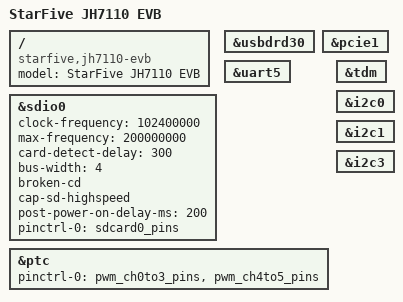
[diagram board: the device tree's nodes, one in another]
// SPDX-License-Identifier: GPL-2.0 OR MIT
/*
 * Copyright (C) 2022 StarFive Technology Co., Ltd.
 * Copyright (C) 2022 Hal Feng <hal.feng@starfivetech.com>
 */

/dts-v1/;
#include "jh7110-evb.dtsi"
#include "codecs/sf_tdm.dtsi"

/ {
	model = "StarFive JH7110 EVB";
	compatible = "starfive,jh7110-evb", "starfive,jh7110";
};

/* default sd card */
&sdio0 {
	clock-frequency = <102400000>;
	max-frequency = <200000000>;
	card-detect-delay = <300>;
	bus-width = <4>;
	broken-cd;
	cap-sd-highspeed;
	post-power-on-delay-ms = <200>;
	pinctrl-names = "default";
	pinctrl-0 = <&sdcard0_pins>;
	status = "okay";
};

&usbdrd30 {
	status = "okay";
};

&pcie1 {
	status = "okay";
};

&uart5 {
	status = "okay";
};

&ptc {
	pinctrl-names = "default";
	pinctrl-0 = <&pwm_ch0to3_pins &pwm_ch4to5_pins>;
	status = "okay";
};

&tdm {
	status = "okay";
};

&i2c0 {
	status = "okay";
};

&i2c1 {
	status = "okay";
};

&i2c3 {
	status = "okay";
};
